AUTOSAR XML (schema 4-2-1)
standard types defined: boolean, float32, sint16, sint8, uint16, uint8, boolean_CompuMethod, boolean_DataConstr, float32_DataConstr, sint16_DataConstr, sint8_DataConstr, uint16_DataConstr, uint8_DataConstr
package /ComponentTypes
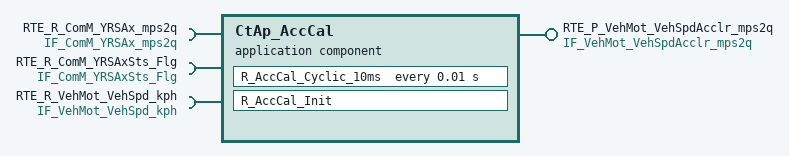
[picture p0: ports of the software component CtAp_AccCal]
  application sw component type CtAp_AccCal
    provide port RTE_P_VehMot_VehSpdAcclr_mps2q: nonqueued-sender-com-spec{data-element=tec_VehMot_VehSpdAcclr_mps2q, init-value=0}, provided-interface=IF_VehMot_VehSpdAcclr_mps2q
    require port RTE_R_ComM_YRSAx_mps2q: nonqueued-receiver-com-spec{data-element=tec_ComM_YRSAx_mps2q, filter=data-filter-type=ALWAYS, init-value=0}, required-interface=IF_ComM_YRSAx_mps2q
    require port RTE_R_ComM_YRSAxSts_Flg: nonqueued-receiver-com-spec{data-element=tec_ComM_YRSAxSts_Flg, filter=data-filter-type=ALWAYS, init-value=0}, required-interface=IF_ComM_YRSAxSts_Flg
    require port RTE_R_VehMot_VehSpd_kph: nonqueued-receiver-com-spec{data-element=tec_VehMot_VehSpd_kph, filter=data-filter-type=ALWAYS, init-value=0}, required-interface=IF_VehMot_VehSpd_kph
    behavior CtAp_AccCal_InternalBehavior
      timing event TMT_R_AccCal_Cyclic_10ms: start-on-event=R_AccCal_Cyclic_10ms, period=0.01
      init event CtAp_AccCal_InitEvent: start-on-event=R_AccCal_Init
      runnable R_AccCal_Cyclic_10ms
        data-receive-point-by-arguments:
          access REC_RTE_R_ComM_YRSAx_mps2q_tec_ComM_YRSAx_mps2q: accessed-variable=RTE_R_ComM_YRSAx_mps2q.tec_ComM_YRSAx_mps2q
          access REC_RTE_R_ComM_YRSAxSts_Flg_tec_ComM_YRSAxSts_Flg: accessed-variable=RTE_R_ComM_YRSAxSts_Flg.tec_ComM_YRSAxSts_Flg
          access REC_RTE_R_VehMot_VehSpd_kph_tec_VehMot_VehSpd_kph: accessed-variable=RTE_R_VehMot_VehSpd_kph.tec_VehMot_VehSpd_kph
        data-send-points:
          access SEND_RTE_P_VehMot_VehSpdAcclr_mps2q_tec_VehMot_VehSpdAcclr_mps2q: accessed-variable=RTE_P_VehMot_VehSpdAcclr_mps2q.tec_VehMot_VehSpdAcclr_mps2q
      runnable R_AccCal_Init
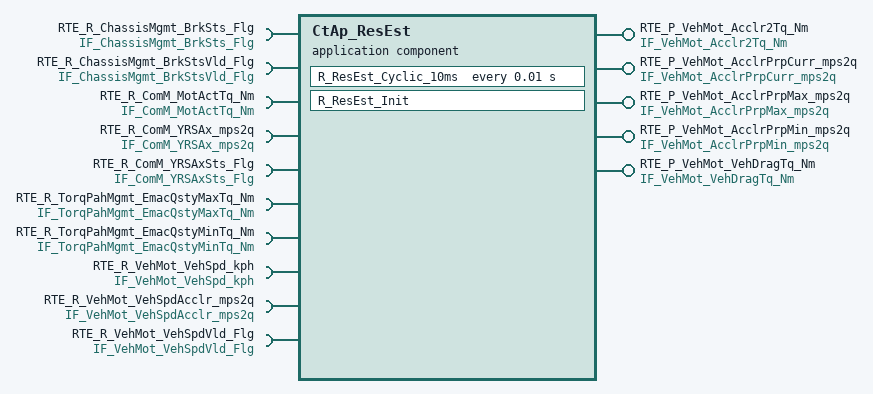
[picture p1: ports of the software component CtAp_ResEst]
  application sw component type CtAp_ResEst
    5 x provide port:
      RTE_P_VehMot_Acclr2Tq_Nm: nonqueued-sender-com-spec{data-element=tec_VehMot_Acclr2Tq_Nm, init-value=0}, provided-interface=IF_VehMot_Acclr2Tq_Nm
      RTE_P_VehMot_AcclrPrpCurr_mps2q: nonqueued-sender-com-spec{data-element=tec_VehMot_AcclrPrpCurr_mps2q, init-value=0}, provided-interface=IF_VehMot_AcclrPrpCurr_mps2q
      RTE_P_VehMot_AcclrPrpMax_mps2q: nonqueued-sender-com-spec{data-element=tec_VehMot_AcclrPrpMax_mps2q, init-value=0}, provided-interface=IF_VehMot_AcclrPrpMax_mps2q
      RTE_P_VehMot_AcclrPrpMin_mps2q: nonqueued-sender-com-spec{data-element=tec_VehMot_AcclrPrpMin_mps2q, init-value=0}, provided-interface=IF_VehMot_AcclrPrpMin_mps2q
      RTE_P_VehMot_VehDragTq_Nm: nonqueued-sender-com-spec{data-element=tec_VehMot_VehDragTq_Nm, init-value=0}, provided-interface=IF_VehMot_VehDragTq_Nm
    10 x require port:
      RTE_R_ChassisMgmt_BrkSts_Flg: nonqueued-receiver-com-spec{data-element=tec_ChassisMgmt_BrkSts_Flg, filter=data-filter-type=ALWAYS, init-value=0}, required-interface=IF_ChassisMgmt_BrkSts_Flg
      RTE_R_ChassisMgmt_BrkStsVld_Flg: nonqueued-receiver-com-spec{data-element=tec_ChassisMgmt_BrkStsVld_Flg, filter=data-filter-type=ALWAYS, init-value=0}, required-interface=IF_ChassisMgmt_BrkStsVld_Flg
      RTE_R_ComM_MotActTq_Nm: nonqueued-receiver-com-spec{data-element=tec_ComM_MotActTq_Nm, filter=data-filter-type=ALWAYS, init-value=0}, required-interface=IF_ComM_MotActTq_Nm
      RTE_R_ComM_YRSAx_mps2q: nonqueued-receiver-com-spec{data-element=tec_ComM_YRSAx_mps2q, filter=data-filter-type=ALWAYS, init-value=0}, required-interface=IF_ComM_YRSAx_mps2q
      RTE_R_ComM_YRSAxSts_Flg: nonqueued-receiver-com-spec{data-element=tec_ComM_YRSAxSts_Flg, filter=data-filter-type=ALWAYS, init-value=0}, required-interface=IF_ComM_YRSAxSts_Flg
      RTE_R_TorqPahMgmt_EmacQstyMaxTq_Nm: nonqueued-receiver-com-spec{data-element=tec_TorqPahMgmt_EmacQstyMaxTq_Nm, filter=data-filter-type=ALWAYS, init-value=0}, required-interface=IF_TorqPahMgmt_EmacQstyMaxTq_Nm
      RTE_R_TorqPahMgmt_EmacQstyMinTq_Nm: nonqueued-receiver-com-spec{data-element=tec_TorqPahMgmt_EmacQstyMinTq_Nm, filter=data-filter-type=ALWAYS, init-value=0}, required-interface=IF_TorqPahMgmt_EmacQstyMinTq_Nm
      RTE_R_VehMot_VehSpd_kph: nonqueued-receiver-com-spec{data-element=tec_VehMot_VehSpd_kph, filter=data-filter-type=ALWAYS, init-value=0}, required-interface=IF_VehMot_VehSpd_kph
      RTE_R_VehMot_VehSpdAcclr_mps2q: nonqueued-receiver-com-spec{data-element=tec_VehMot_VehSpdAcclr_mps2q, filter=data-filter-type=ALWAYS, init-value=0}, required-interface=IF_VehMot_VehSpdAcclr_mps2q
      RTE_R_VehMot_VehSpdVld_Flg: nonqueued-receiver-com-spec{data-element=tec_VehMot_VehSpdVld_Flg, filter=data-filter-type=ALWAYS, init-value=0}, required-interface=IF_VehMot_VehSpdVld_Flg
    behavior CtAp_ResEst_InternalBehavior
      timing event TMT_R_ResEst_Cyclic_10ms: start-on-event=R_ResEst_Cyclic_10ms, period=0.01
      init event CtAp_ResEst_InitEvent: start-on-event=R_ResEst_Init
      runnable R_ResEst_Cyclic_10ms
        data-receive-point-by-arguments:
          10 x access:
            REC_RTE_R_ChassisMgmt_BrkSts_Flg_tec_ChassisMgmt_BrkSts_Flg: accessed-variable=RTE_R_ChassisMgmt_BrkSts_Flg.tec_ChassisMgmt_BrkSts_Flg
            REC_RTE_R_ChassisMgmt_BrkStsVld_Flg_tec_ChassisMgmt_BrkStsVld_Flg: accessed-variable=RTE_R_ChassisMgmt_BrkStsVld_Flg.tec_ChassisMgmt_BrkStsVld_Flg
            REC_RTE_R_ComM_MotActTq_Nm_tec_ComM_MotActTq_Nm: accessed-variable=RTE_R_ComM_MotActTq_Nm.tec_ComM_MotActTq_Nm
            REC_RTE_R_ComM_YRSAx_mps2q_tec_ComM_YRSAx_mps2q: accessed-variable=RTE_R_ComM_YRSAx_mps2q.tec_ComM_YRSAx_mps2q
            REC_RTE_R_ComM_YRSAxSts_Flg_tec_ComM_YRSAxSts_Flg: accessed-variable=RTE_R_ComM_YRSAxSts_Flg.tec_ComM_YRSAxSts_Flg
            REC_RTE_R_TorqPahMgmt_EmacQstyMaxTq_Nm_tec_TorqPahMgmt_EmacQstyMaxTq_Nm: accessed-variable=RTE_R_TorqPahMgmt_EmacQstyMaxTq_Nm.tec_TorqPahMgmt_EmacQstyMaxTq_Nm
            REC_RTE_R_TorqPahMgmt_EmacQstyMinTq_Nm_tec_TorqPahMgmt_EmacQstyMinTq_Nm: accessed-variable=RTE_R_TorqPahMgmt_EmacQstyMinTq_Nm.tec_TorqPahMgmt_EmacQstyMinTq_Nm
            REC_RTE_R_VehMot_VehSpd_kph_tec_VehMot_VehSpd_kph: accessed-variable=RTE_R_VehMot_VehSpd_kph.tec_VehMot_VehSpd_kph
            REC_RTE_R_VehMot_VehSpdAcclr_mps2q_tec_VehMot_VehSpdAcclr_mps2q: accessed-variable=RTE_R_VehMot_VehSpdAcclr_mps2q.tec_VehMot_VehSpdAcclr_mps2q
            REC_RTE_R_VehMot_VehSpdVld_Flg_tec_VehMot_VehSpdVld_Flg: accessed-variable=RTE_R_VehMot_VehSpdVld_Flg.tec_VehMot_VehSpdVld_Flg
        data-send-points:
          5 x access:
            SEND_RTE_P_VehMot_Acclr2Tq_Nm_tec_VehMot_Acclr2Tq_Nm: accessed-variable=RTE_P_VehMot_Acclr2Tq_Nm.tec_VehMot_Acclr2Tq_Nm
            SEND_RTE_P_VehMot_AcclrPrpCurr_mps2q_tec_VehMot_AcclrPrpCurr_mps2q: accessed-variable=RTE_P_VehMot_AcclrPrpCurr_mps2q.tec_VehMot_AcclrPrpCurr_mps2q
            SEND_RTE_P_VehMot_AcclrPrpMax_mps2q_tec_VehMot_AcclrPrpMax_mps2q: accessed-variable=RTE_P_VehMot_AcclrPrpMax_mps2q.tec_VehMot_AcclrPrpMax_mps2q
            SEND_RTE_P_VehMot_AcclrPrpMin_mps2q_tec_VehMot_AcclrPrpMin_mps2q: accessed-variable=RTE_P_VehMot_AcclrPrpMin_mps2q.tec_VehMot_AcclrPrpMin_mps2q
            SEND_RTE_P_VehMot_VehDragTq_Nm_tec_VehMot_VehDragTq_Nm: accessed-variable=RTE_P_VehMot_VehDragTq_Nm.tec_VehMot_VehDragTq_Nm
      runnable R_ResEst_Init
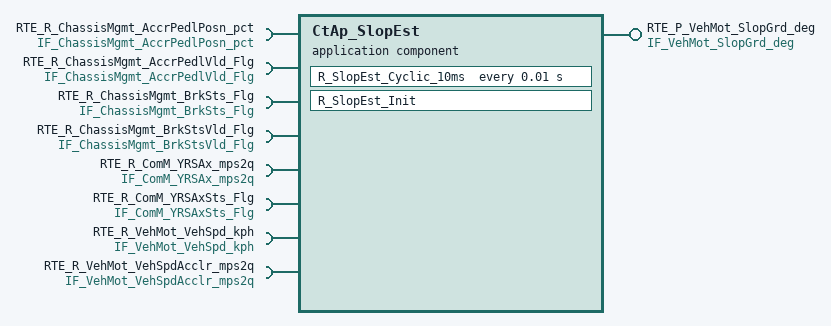
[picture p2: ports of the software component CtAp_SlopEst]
  application sw component type CtAp_SlopEst
    provide port RTE_P_VehMot_SlopGrd_deg: nonqueued-sender-com-spec{data-element=tec_VehMot_SlopGrd_deg, init-value=0}, provided-interface=IF_VehMot_SlopGrd_deg
    8 x require port:
      RTE_R_ChassisMgmt_AccrPedlPosn_pct: nonqueued-receiver-com-spec{data-element=tec_ChassisMgmt_AccrPedlPosn_pct, filter=data-filter-type=ALWAYS, init-value=0}, required-interface=IF_ChassisMgmt_AccrPedlPosn_pct
      RTE_R_ChassisMgmt_AccrPedlVld_Flg: nonqueued-receiver-com-spec{data-element=tec_ChassisMgmt_AccrPedlVld_Flg, filter=data-filter-type=ALWAYS, init-value=0}, required-interface=IF_ChassisMgmt_AccrPedlVld_Flg
      RTE_R_ChassisMgmt_BrkSts_Flg: nonqueued-receiver-com-spec{data-element=tec_ChassisMgmt_BrkSts_Flg, filter=data-filter-type=ALWAYS, init-value=0}, required-interface=IF_ChassisMgmt_BrkSts_Flg
      RTE_R_ChassisMgmt_BrkStsVld_Flg: nonqueued-receiver-com-spec{data-element=tec_ChassisMgmt_BrkStsVld_Flg, filter=data-filter-type=ALWAYS, init-value=0}, required-interface=IF_ChassisMgmt_BrkStsVld_Flg
      RTE_R_ComM_YRSAx_mps2q: nonqueued-receiver-com-spec{data-element=tec_ComM_YRSAx_mps2q, filter=data-filter-type=ALWAYS, init-value=0}, required-interface=IF_ComM_YRSAx_mps2q
      RTE_R_ComM_YRSAxSts_Flg: nonqueued-receiver-com-spec{data-element=tec_ComM_YRSAxSts_Flg, filter=data-filter-type=ALWAYS, init-value=0}, required-interface=IF_ComM_YRSAxSts_Flg
      RTE_R_VehMot_VehSpd_kph: nonqueued-receiver-com-spec{data-element=tec_VehMot_VehSpd_kph, filter=data-filter-type=ALWAYS, init-value=0}, required-interface=IF_VehMot_VehSpd_kph
      RTE_R_VehMot_VehSpdAcclr_mps2q: nonqueued-receiver-com-spec{data-element=tec_VehMot_VehSpdAcclr_mps2q, filter=data-filter-type=ALWAYS, init-value=0}, required-interface=IF_VehMot_VehSpdAcclr_mps2q
    behavior CtAp_SlopEst_InternalBehavior
      timing event TMT_R_SlopEst_Cyclic_10ms: start-on-event=R_SlopEst_Cyclic_10ms, period=0.01
      init event CtAp_SlopEst_InitEvent: start-on-event=R_SlopEst_Init
      runnable R_SlopEst_Cyclic_10ms
        data-receive-point-by-arguments:
          8 x access:
            REC_RTE_R_ChassisMgmt_AccrPedlPosn_pct_tec_ChassisMgmt_AccrPedlPosn_pct: accessed-variable=RTE_R_ChassisMgmt_AccrPedlPosn_pct.tec_ChassisMgmt_AccrPedlPosn_pct
            REC_RTE_R_ChassisMgmt_AccrPedlVld_Flg_tec_ChassisMgmt_AccrPedlVld_Flg: accessed-variable=RTE_R_ChassisMgmt_AccrPedlVld_Flg.tec_ChassisMgmt_AccrPedlVld_Flg
            REC_RTE_R_ChassisMgmt_BrkSts_Flg_tec_ChassisMgmt_BrkSts_Flg: accessed-variable=RTE_R_ChassisMgmt_BrkSts_Flg.tec_ChassisMgmt_BrkSts_Flg
            REC_RTE_R_ChassisMgmt_BrkStsVld_Flg_tec_ChassisMgmt_BrkStsVld_Flg: accessed-variable=RTE_R_ChassisMgmt_BrkStsVld_Flg.tec_ChassisMgmt_BrkStsVld_Flg
            REC_RTE_R_ComM_YRSAx_mps2q_tec_ComM_YRSAx_mps2q: accessed-variable=RTE_R_ComM_YRSAx_mps2q.tec_ComM_YRSAx_mps2q
            REC_RTE_R_ComM_YRSAxSts_Flg_tec_ComM_YRSAxSts_Flg: accessed-variable=RTE_R_ComM_YRSAxSts_Flg.tec_ComM_YRSAxSts_Flg
            REC_RTE_R_VehMot_VehSpd_kph_tec_VehMot_VehSpd_kph: accessed-variable=RTE_R_VehMot_VehSpd_kph.tec_VehMot_VehSpd_kph
            REC_RTE_R_VehMot_VehSpdAcclr_mps2q_tec_VehMot_VehSpdAcclr_mps2q: accessed-variable=RTE_R_VehMot_VehSpdAcclr_mps2q.tec_VehMot_VehSpdAcclr_mps2q
        data-send-points:
          access SEND_RTE_P_VehMot_SlopGrd_deg_tec_VehMot_SlopGrd_deg: accessed-variable=RTE_P_VehMot_SlopGrd_deg.tec_VehMot_SlopGrd_deg
      runnable R_SlopEst_Init
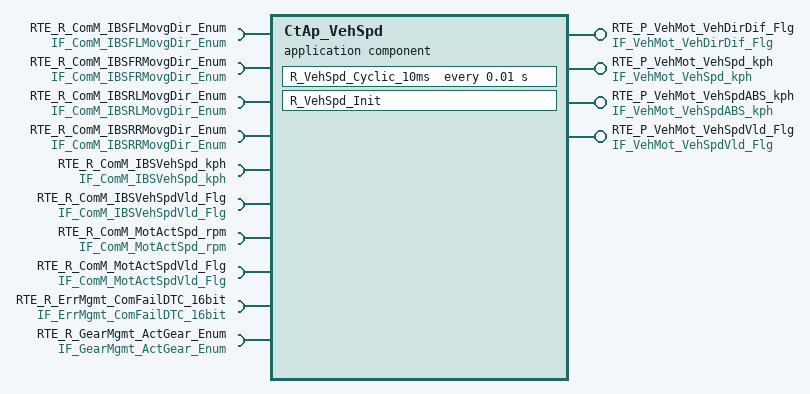
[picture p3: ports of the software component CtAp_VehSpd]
  application sw component type CtAp_VehSpd
    4 x provide port:
      RTE_P_VehMot_VehDirDif_Flg: nonqueued-sender-com-spec{data-element=tec_VehMot_VehDirDif_Flg, init-value=0}, provided-interface=IF_VehMot_VehDirDif_Flg
      RTE_P_VehMot_VehSpd_kph: nonqueued-sender-com-spec{data-element=tec_VehMot_VehSpd_kph, init-value=0}, provided-interface=IF_VehMot_VehSpd_kph
      RTE_P_VehMot_VehSpdABS_kph: nonqueued-sender-com-spec{data-element=tec_VehMot_VehSpdABS_kph, init-value=0}, provided-interface=IF_VehMot_VehSpdABS_kph
      RTE_P_VehMot_VehSpdVld_Flg: nonqueued-sender-com-spec{data-element=tec_VehMot_VehSpdVld_Flg, init-value=0}, provided-interface=IF_VehMot_VehSpdVld_Flg
    10 x require port:
      RTE_R_ComM_IBSFLMovgDir_Enum: nonqueued-receiver-com-spec{data-element=tec_ComM_IBSFLMovgDir_Enum, filter=data-filter-type=ALWAYS, init-value=0}, required-interface=IF_ComM_IBSFLMovgDir_Enum
      RTE_R_ComM_IBSFRMovgDir_Enum: nonqueued-receiver-com-spec{data-element=tec_ComM_IBSFRMovgDir_Enum, filter=data-filter-type=ALWAYS, init-value=0}, required-interface=IF_ComM_IBSFRMovgDir_Enum
      RTE_R_ComM_IBSRLMovgDir_Enum: nonqueued-receiver-com-spec{data-element=tec_ComM_IBSRLMovgDir_Enum, filter=data-filter-type=ALWAYS, init-value=0}, required-interface=IF_ComM_IBSRLMovgDir_Enum
      RTE_R_ComM_IBSRRMovgDir_Enum: nonqueued-receiver-com-spec{data-element=tec_ComM_IBSRRMovgDir_Enum, filter=data-filter-type=ALWAYS, init-value=0}, required-interface=IF_ComM_IBSRRMovgDir_Enum
      RTE_R_ComM_IBSVehSpd_kph: nonqueued-receiver-com-spec{data-element=tec_ComM_IBSVehSpd_kph, filter=data-filter-type=ALWAYS, init-value=0}, required-interface=IF_ComM_IBSVehSpd_kph
      RTE_R_ComM_IBSVehSpdVld_Flg: nonqueued-receiver-com-spec{data-element=tec_ComM_IBSVehSpdVld_Flg, filter=data-filter-type=ALWAYS, init-value=0}, required-interface=IF_ComM_IBSVehSpdVld_Flg
      RTE_R_ComM_MotActSpd_rpm: nonqueued-receiver-com-spec{data-element=tec_ComM_MotActSpd_rpm, filter=data-filter-type=ALWAYS, init-value=0}, required-interface=IF_ComM_MotActSpd_rpm
      RTE_R_ComM_MotActSpdVld_Flg: nonqueued-receiver-com-spec{data-element=tec_ComM_MotActSpdVld_Flg, filter=data-filter-type=ALWAYS, init-value=0}, required-interface=IF_ComM_MotActSpdVld_Flg
      RTE_R_ErrMgmt_ComFailDTC_16bit: nonqueued-receiver-com-spec{data-element=tec_ErrMgmt_ComFailDTC_16bit, filter=data-filter-type=ALWAYS, init-value=0}, required-interface=IF_ErrMgmt_ComFailDTC_16bit
      RTE_R_GearMgmt_ActGear_Enum: nonqueued-receiver-com-spec{data-element=tec_GearMgmt_ActGear_Enum, filter=data-filter-type=ALWAYS, init-value=0}, required-interface=IF_GearMgmt_ActGear_Enum
    behavior CtAp_VehSpd_InternalBehavior
      timing event TMT_R_VehSpd_Cyclic_10ms: start-on-event=R_VehSpd_Cyclic_10ms, period=0.01
      init event CtAp_VehSpd_InitEvent: start-on-event=R_VehSpd_Init
      runnable R_VehSpd_Cyclic_10ms
        data-receive-point-by-arguments:
          10 x access:
            REC_RTE_R_ComM_IBSFLMovgDir_Enum_tec_ComM_IBSFLMovgDir_Enum: accessed-variable=RTE_R_ComM_IBSFLMovgDir_Enum.tec_ComM_IBSFLMovgDir_Enum
            REC_RTE_R_ComM_IBSFRMovgDir_Enum_tec_ComM_IBSFRMovgDir_Enum: accessed-variable=RTE_R_ComM_IBSFRMovgDir_Enum.tec_ComM_IBSFRMovgDir_Enum
            REC_RTE_R_ComM_IBSRLMovgDir_Enum_tec_ComM_IBSRLMovgDir_Enum: accessed-variable=RTE_R_ComM_IBSRLMovgDir_Enum.tec_ComM_IBSRLMovgDir_Enum
            REC_RTE_R_ComM_IBSRRMovgDir_Enum_tec_ComM_IBSRRMovgDir_Enum: accessed-variable=RTE_R_ComM_IBSRRMovgDir_Enum.tec_ComM_IBSRRMovgDir_Enum
            REC_RTE_R_ComM_IBSVehSpd_kph_tec_ComM_IBSVehSpd_kph: accessed-variable=RTE_R_ComM_IBSVehSpd_kph.tec_ComM_IBSVehSpd_kph
            REC_RTE_R_ComM_IBSVehSpdVld_Flg_tec_ComM_IBSVehSpdVld_Flg: accessed-variable=RTE_R_ComM_IBSVehSpdVld_Flg.tec_ComM_IBSVehSpdVld_Flg
            REC_RTE_R_ComM_MotActSpd_rpm_tec_ComM_MotActSpd_rpm: accessed-variable=RTE_R_ComM_MotActSpd_rpm.tec_ComM_MotActSpd_rpm
            REC_RTE_R_ComM_MotActSpdVld_Flg_tec_ComM_MotActSpdVld_Flg: accessed-variable=RTE_R_ComM_MotActSpdVld_Flg.tec_ComM_MotActSpdVld_Flg
            REC_RTE_R_ErrMgmt_ComFailDTC_16bit_tec_ErrMgmt_ComFailDTC_16bit: accessed-variable=RTE_R_ErrMgmt_ComFailDTC_16bit.tec_ErrMgmt_ComFailDTC_16bit
            REC_RTE_R_GearMgmt_ActGear_Enum_tec_GearMgmt_ActGear_Enum: accessed-variable=RTE_R_GearMgmt_ActGear_Enum.tec_GearMgmt_ActGear_Enum
        data-send-points:
          4 x access:
            SEND_RTE_P_VehMot_VehDirDif_Flg_tec_VehMot_VehDirDif_Flg: accessed-variable=RTE_P_VehMot_VehDirDif_Flg.tec_VehMot_VehDirDif_Flg
            SEND_RTE_P_VehMot_VehSpd_kph_tec_VehMot_VehSpd_kph: accessed-variable=RTE_P_VehMot_VehSpd_kph.tec_VehMot_VehSpd_kph
            SEND_RTE_P_VehMot_VehSpdABS_kph_tec_VehMot_VehSpdABS_kph: accessed-variable=RTE_P_VehMot_VehSpdABS_kph.tec_VehMot_VehSpdABS_kph
            SEND_RTE_P_VehMot_VehSpdVld_Flg_tec_VehMot_VehSpdVld_Flg: accessed-variable=RTE_P_VehMot_VehSpdVld_Flg.tec_VehMot_VehSpdVld_Flg
      runnable R_VehSpd_Init
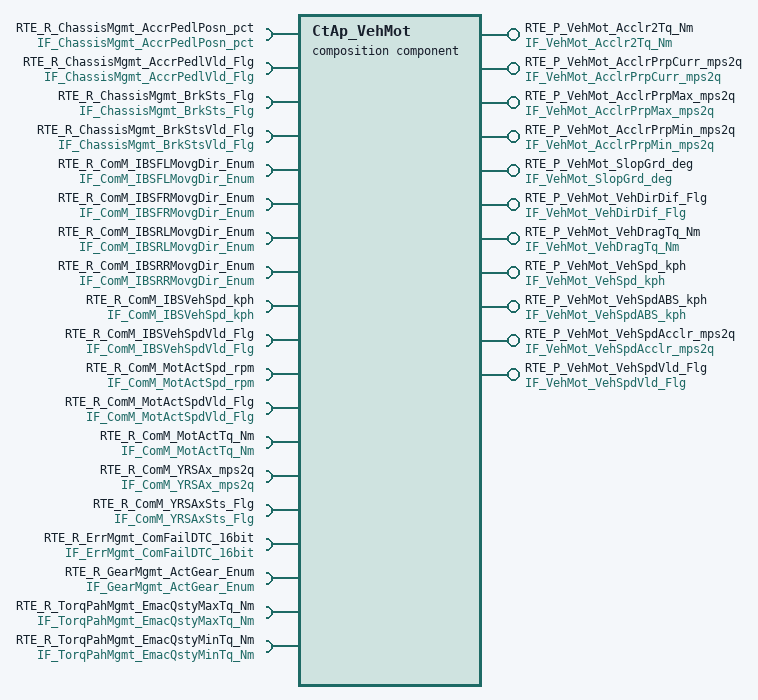
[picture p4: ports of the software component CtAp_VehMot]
  composition sw component type CtAp_VehMot
    11 x provide port:
      RTE_P_VehMot_Acclr2Tq_Nm: nonqueued-sender-com-spec{data-element=tec_VehMot_Acclr2Tq_Nm, init-value=0}, provided-interface=IF_VehMot_Acclr2Tq_Nm
      RTE_P_VehMot_AcclrPrpCurr_mps2q: nonqueued-sender-com-spec{data-element=tec_VehMot_AcclrPrpCurr_mps2q, init-value=0}, provided-interface=IF_VehMot_AcclrPrpCurr_mps2q
      RTE_P_VehMot_AcclrPrpMax_mps2q: nonqueued-sender-com-spec{data-element=tec_VehMot_AcclrPrpMax_mps2q, init-value=0}, provided-interface=IF_VehMot_AcclrPrpMax_mps2q
      RTE_P_VehMot_AcclrPrpMin_mps2q: nonqueued-sender-com-spec{data-element=tec_VehMot_AcclrPrpMin_mps2q, init-value=0}, provided-interface=IF_VehMot_AcclrPrpMin_mps2q
      RTE_P_VehMot_SlopGrd_deg: nonqueued-sender-com-spec{data-element=tec_VehMot_SlopGrd_deg, init-value=0}, provided-interface=IF_VehMot_SlopGrd_deg
      RTE_P_VehMot_VehDirDif_Flg: nonqueued-sender-com-spec{data-element=tec_VehMot_VehDirDif_Flg, init-value=0}, provided-interface=IF_VehMot_VehDirDif_Flg
      RTE_P_VehMot_VehDragTq_Nm: nonqueued-sender-com-spec{data-element=tec_VehMot_VehDragTq_Nm, init-value=0}, provided-interface=IF_VehMot_VehDragTq_Nm
      RTE_P_VehMot_VehSpd_kph: nonqueued-sender-com-spec{data-element=tec_VehMot_VehSpd_kph, init-value=0}, provided-interface=IF_VehMot_VehSpd_kph
      RTE_P_VehMot_VehSpdABS_kph: nonqueued-sender-com-spec{data-element=tec_VehMot_VehSpdABS_kph, init-value=0}, provided-interface=IF_VehMot_VehSpdABS_kph
      RTE_P_VehMot_VehSpdAcclr_mps2q: nonqueued-sender-com-spec{data-element=tec_VehMot_VehSpdAcclr_mps2q, init-value=0}, provided-interface=IF_VehMot_VehSpdAcclr_mps2q
      RTE_P_VehMot_VehSpdVld_Flg: nonqueued-sender-com-spec{data-element=tec_VehMot_VehSpdVld_Flg, init-value=0}, provided-interface=IF_VehMot_VehSpdVld_Flg
    19 x require port:
      RTE_R_ChassisMgmt_AccrPedlPosn_pct: nonqueued-receiver-com-spec{data-element=tec_ChassisMgmt_AccrPedlPosn_pct, filter=data-filter-type=ALWAYS, init-value=0}, required-interface=IF_ChassisMgmt_AccrPedlPosn_pct
      RTE_R_ChassisMgmt_AccrPedlVld_Flg: nonqueued-receiver-com-spec{data-element=tec_ChassisMgmt_AccrPedlVld_Flg, filter=data-filter-type=ALWAYS, init-value=0}, required-interface=IF_ChassisMgmt_AccrPedlVld_Flg
      RTE_R_ChassisMgmt_BrkSts_Flg: nonqueued-receiver-com-spec{data-element=tec_ChassisMgmt_BrkSts_Flg, filter=data-filter-type=ALWAYS, init-value=0}, required-interface=IF_ChassisMgmt_BrkSts_Flg
      RTE_R_ChassisMgmt_BrkStsVld_Flg: nonqueued-receiver-com-spec{data-element=tec_ChassisMgmt_BrkStsVld_Flg, filter=data-filter-type=ALWAYS, init-value=0}, required-interface=IF_ChassisMgmt_BrkStsVld_Flg
      RTE_R_ComM_IBSFLMovgDir_Enum: nonqueued-receiver-com-spec{data-element=tec_ComM_IBSFLMovgDir_Enum, filter=data-filter-type=ALWAYS, init-value=0}, required-interface=IF_ComM_IBSFLMovgDir_Enum
      RTE_R_ComM_IBSFRMovgDir_Enum: nonqueued-receiver-com-spec{data-element=tec_ComM_IBSFRMovgDir_Enum, filter=data-filter-type=ALWAYS, init-value=0}, required-interface=IF_ComM_IBSFRMovgDir_Enum
      RTE_R_ComM_IBSRLMovgDir_Enum: nonqueued-receiver-com-spec{data-element=tec_ComM_IBSRLMovgDir_Enum, filter=data-filter-type=ALWAYS, init-value=0}, required-interface=IF_ComM_IBSRLMovgDir_Enum
      RTE_R_ComM_IBSRRMovgDir_Enum: nonqueued-receiver-com-spec{data-element=tec_ComM_IBSRRMovgDir_Enum, filter=data-filter-type=ALWAYS, init-value=0}, required-interface=IF_ComM_IBSRRMovgDir_Enum
      RTE_R_ComM_IBSVehSpd_kph: nonqueued-receiver-com-spec{data-element=tec_ComM_IBSVehSpd_kph, filter=data-filter-type=ALWAYS, init-value=0}, required-interface=IF_ComM_IBSVehSpd_kph
      RTE_R_ComM_IBSVehSpdVld_Flg: nonqueued-receiver-com-spec{data-element=tec_ComM_IBSVehSpdVld_Flg, filter=data-filter-type=ALWAYS, init-value=0}, required-interface=IF_ComM_IBSVehSpdVld_Flg
      RTE_R_ComM_MotActSpd_rpm: nonqueued-receiver-com-spec{data-element=tec_ComM_MotActSpd_rpm, filter=data-filter-type=ALWAYS, init-value=0}, required-interface=IF_ComM_MotActSpd_rpm
      RTE_R_ComM_MotActSpdVld_Flg: nonqueued-receiver-com-spec{data-element=tec_ComM_MotActSpdVld_Flg, filter=data-filter-type=ALWAYS, init-value=0}, required-interface=IF_ComM_MotActSpdVld_Flg
      RTE_R_ComM_MotActTq_Nm: nonqueued-receiver-com-spec{data-element=tec_ComM_MotActTq_Nm, filter=data-filter-type=ALWAYS, init-value=0}, required-interface=IF_ComM_MotActTq_Nm
      RTE_R_ComM_YRSAx_mps2q: nonqueued-receiver-com-spec{data-element=tec_ComM_YRSAx_mps2q, filter=data-filter-type=ALWAYS, init-value=0}, required-interface=IF_ComM_YRSAx_mps2q
      RTE_R_ComM_YRSAxSts_Flg: nonqueued-receiver-com-spec{data-element=tec_ComM_YRSAxSts_Flg, filter=data-filter-type=ALWAYS, init-value=0}, required-interface=IF_ComM_YRSAxSts_Flg
      RTE_R_ErrMgmt_ComFailDTC_16bit: nonqueued-receiver-com-spec{data-element=tec_ErrMgmt_ComFailDTC_16bit, filter=data-filter-type=ALWAYS, init-value=0}, required-interface=IF_ErrMgmt_ComFailDTC_16bit
      RTE_R_GearMgmt_ActGear_Enum: nonqueued-receiver-com-spec{data-element=tec_GearMgmt_ActGear_Enum, filter=data-filter-type=ALWAYS, init-value=0}, required-interface=IF_GearMgmt_ActGear_Enum
      RTE_R_TorqPahMgmt_EmacQstyMaxTq_Nm: nonqueued-receiver-com-spec{data-element=tec_TorqPahMgmt_EmacQstyMaxTq_Nm, filter=data-filter-type=ALWAYS, init-value=0}, required-interface=IF_TorqPahMgmt_EmacQstyMaxTq_Nm
      RTE_R_TorqPahMgmt_EmacQstyMinTq_Nm: nonqueued-receiver-com-spec{data-element=tec_TorqPahMgmt_EmacQstyMinTq_Nm, filter=data-filter-type=ALWAYS, init-value=0}, required-interface=IF_TorqPahMgmt_EmacQstyMinTq_Nm
    4 x component:
      CtAp_AccCal: type=CtAp_AccCal
      CtAp_ResEst: type=CtAp_ResEst
      CtAp_SlopEst: type=CtAp_SlopEst
      CtAp_VehSpd: type=CtAp_VehSpd
    connect CtAp_AccCal.RTE_P_VehMot_VehSpdAcclr_mps2q -> CtAp_ResEst.RTE_R_VehMot_VehSpdAcclr_mps2q
    connect CtAp_AccCal.RTE_P_VehMot_VehSpdAcclr_mps2q -> CtAp_SlopEst.RTE_R_VehMot_VehSpdAcclr_mps2q
    connect CtAp_VehSpd.RTE_P_VehMot_VehSpd_kph -> CtAp_AccCal.RTE_R_VehMot_VehSpd_kph
    connect CtAp_VehSpd.RTE_P_VehMot_VehSpd_kph -> CtAp_ResEst.RTE_R_VehMot_VehSpd_kph
    connect CtAp_VehSpd.RTE_P_VehMot_VehSpdVld_Flg -> CtAp_ResEst.RTE_R_VehMot_VehSpdVld_Flg
    connect CtAp_VehSpd.RTE_P_VehMot_VehSpd_kph -> CtAp_SlopEst.RTE_R_VehMot_VehSpd_kph
    delegate CtAp_ResEst.RTE_P_VehMot_Acclr2Tq_Nm <-> outer port CtAp_VehMot/RTE_P_VehMot_Acclr2Tq_Nm
    delegate CtAp_ResEst.RTE_P_VehMot_AcclrPrpCurr_mps2q <-> outer port CtAp_VehMot/RTE_P_VehMot_AcclrPrpCurr_mps2q
    delegate CtAp_ResEst.RTE_P_VehMot_AcclrPrpMax_mps2q <-> outer port CtAp_VehMot/RTE_P_VehMot_AcclrPrpMax_mps2q
    delegate CtAp_ResEst.RTE_P_VehMot_AcclrPrpMin_mps2q <-> outer port CtAp_VehMot/RTE_P_VehMot_AcclrPrpMin_mps2q
    delegate CtAp_SlopEst.RTE_P_VehMot_SlopGrd_deg <-> outer port CtAp_VehMot/RTE_P_VehMot_SlopGrd_deg
    delegate CtAp_VehSpd.RTE_P_VehMot_VehDirDif_Flg <-> outer port CtAp_VehMot/RTE_P_VehMot_VehDirDif_Flg
    delegate CtAp_ResEst.RTE_P_VehMot_VehDragTq_Nm <-> outer port CtAp_VehMot/RTE_P_VehMot_VehDragTq_Nm
    delegate CtAp_VehSpd.RTE_P_VehMot_VehSpd_kph <-> outer port CtAp_VehMot/RTE_P_VehMot_VehSpd_kph
    delegate CtAp_VehSpd.RTE_P_VehMot_VehSpdABS_kph <-> outer port CtAp_VehMot/RTE_P_VehMot_VehSpdABS_kph
    delegate CtAp_AccCal.RTE_P_VehMot_VehSpdAcclr_mps2q <-> outer port CtAp_VehMot/RTE_P_VehMot_VehSpdAcclr_mps2q
    delegate CtAp_VehSpd.RTE_P_VehMot_VehSpdVld_Flg <-> outer port CtAp_VehMot/RTE_P_VehMot_VehSpdVld_Flg
    delegate CtAp_SlopEst.RTE_R_ChassisMgmt_AccrPedlPosn_pct <-> outer port CtAp_VehMot/RTE_R_ChassisMgmt_AccrPedlPosn_pct
    delegate CtAp_SlopEst.RTE_R_ChassisMgmt_AccrPedlVld_Flg <-> outer port CtAp_VehMot/RTE_R_ChassisMgmt_AccrPedlVld_Flg
    delegate CtAp_ResEst.RTE_R_ChassisMgmt_BrkSts_Flg <-> outer port CtAp_VehMot/RTE_R_ChassisMgmt_BrkSts_Flg
    delegate CtAp_SlopEst.RTE_R_ChassisMgmt_BrkSts_Flg <-> outer port CtAp_VehMot/RTE_R_ChassisMgmt_BrkSts_Flg
    delegate CtAp_ResEst.RTE_R_ChassisMgmt_BrkStsVld_Flg <-> outer port CtAp_VehMot/RTE_R_ChassisMgmt_BrkStsVld_Flg
    delegate CtAp_SlopEst.RTE_R_ChassisMgmt_BrkStsVld_Flg <-> outer port CtAp_VehMot/RTE_R_ChassisMgmt_BrkStsVld_Flg
    delegate CtAp_VehSpd.RTE_R_ComM_IBSFLMovgDir_Enum <-> outer port CtAp_VehMot/RTE_R_ComM_IBSFLMovgDir_Enum
    delegate CtAp_VehSpd.RTE_R_ComM_IBSFRMovgDir_Enum <-> outer port CtAp_VehMot/RTE_R_ComM_IBSFRMovgDir_Enum
    delegate CtAp_VehSpd.RTE_R_ComM_IBSRLMovgDir_Enum <-> outer port CtAp_VehMot/RTE_R_ComM_IBSRLMovgDir_Enum
    delegate CtAp_VehSpd.RTE_R_ComM_IBSRRMovgDir_Enum <-> outer port CtAp_VehMot/RTE_R_ComM_IBSRRMovgDir_Enum
    delegate CtAp_VehSpd.RTE_R_ComM_IBSVehSpd_kph <-> outer port CtAp_VehMot/RTE_R_ComM_IBSVehSpd_kph
    delegate CtAp_VehSpd.RTE_R_ComM_IBSVehSpdVld_Flg <-> outer port CtAp_VehMot/RTE_R_ComM_IBSVehSpdVld_Flg
    delegate CtAp_VehSpd.RTE_R_ComM_MotActSpd_rpm <-> outer port CtAp_VehMot/RTE_R_ComM_MotActSpd_rpm
    delegate CtAp_VehSpd.RTE_R_ComM_MotActSpdVld_Flg <-> outer port CtAp_VehMot/RTE_R_ComM_MotActSpdVld_Flg
    delegate CtAp_ResEst.RTE_R_ComM_MotActTq_Nm <-> outer port CtAp_VehMot/RTE_R_ComM_MotActTq_Nm
    delegate CtAp_AccCal.RTE_R_ComM_YRSAx_mps2q <-> outer port CtAp_VehMot/RTE_R_ComM_YRSAx_mps2q
    delegate CtAp_ResEst.RTE_R_ComM_YRSAx_mps2q <-> outer port CtAp_VehMot/RTE_R_ComM_YRSAx_mps2q
    delegate CtAp_SlopEst.RTE_R_ComM_YRSAx_mps2q <-> outer port CtAp_VehMot/RTE_R_ComM_YRSAx_mps2q
    delegate CtAp_AccCal.RTE_R_ComM_YRSAxSts_Flg <-> outer port CtAp_VehMot/RTE_R_ComM_YRSAxSts_Flg
    delegate CtAp_ResEst.RTE_R_ComM_YRSAxSts_Flg <-> outer port CtAp_VehMot/RTE_R_ComM_YRSAxSts_Flg
    delegate CtAp_SlopEst.RTE_R_ComM_YRSAxSts_Flg <-> outer port CtAp_VehMot/RTE_R_ComM_YRSAxSts_Flg
    delegate CtAp_VehSpd.RTE_R_ErrMgmt_ComFailDTC_16bit <-> outer port CtAp_VehMot/RTE_R_ErrMgmt_ComFailDTC_16bit
    delegate CtAp_VehSpd.RTE_R_GearMgmt_ActGear_Enum <-> outer port CtAp_VehMot/RTE_R_GearMgmt_ActGear_Enum
    delegate CtAp_ResEst.RTE_R_TorqPahMgmt_EmacQstyMaxTq_Nm <-> outer port CtAp_VehMot/RTE_R_TorqPahMgmt_EmacQstyMaxTq_Nm
    delegate CtAp_ResEst.RTE_R_TorqPahMgmt_EmacQstyMinTq_Nm <-> outer port CtAp_VehMot/RTE_R_TorqPahMgmt_EmacQstyMinTq_Nm
  4 x swc implementation:
    CtAp_AccCal_Implementation: behavior=CtAp_AccCal_InternalBehavior
      code-descriptors:
        code Default: artifact-descriptors=autosar-engineering-object={short-label=Default, category=SWOBJ}
    CtAp_ResEst_Implementation: behavior=CtAp_ResEst_InternalBehavior
      code-descriptors:
        code Default: artifact-descriptors=autosar-engineering-object={short-label=Default, category=SWOBJ}
    CtAp_SlopEst_Implementation: behavior=CtAp_SlopEst_InternalBehavior
      code-descriptors:
        code Default: artifact-descriptors=autosar-engineering-object={short-label=Default, category=SWOBJ}
    CtAp_VehSpd_Implementation: behavior=CtAp_VehSpd_InternalBehavior
      code-descriptors:
        code Default: artifact-descriptors=autosar-engineering-object={short-label=Default, category=SWOBJ}
package /PortInterfaces
  30 x sender receiver interface:
    IF_ChassisMgmt_AccrPedlPosn_pct: invalidation-policy{data-element=tec_ChassisMgmt_AccrPedlPosn_pct, handle-invalid=DONT-INVALIDATE}
      data tec_ChassisMgmt_AccrPedlPosn_pct: type=float32
    IF_ChassisMgmt_AccrPedlVld_Flg: invalidation-policy{data-element=tec_ChassisMgmt_AccrPedlVld_Flg, handle-invalid=DONT-INVALIDATE}
      data tec_ChassisMgmt_AccrPedlVld_Flg: type=boolean
    IF_ChassisMgmt_BrkSts_Flg: invalidation-policy{data-element=tec_ChassisMgmt_BrkSts_Flg, handle-invalid=DONT-INVALIDATE}
      data tec_ChassisMgmt_BrkSts_Flg: type=boolean
    IF_ChassisMgmt_BrkStsVld_Flg: invalidation-policy{data-element=tec_ChassisMgmt_BrkStsVld_Flg, handle-invalid=DONT-INVALIDATE}
      data tec_ChassisMgmt_BrkStsVld_Flg: type=boolean
    IF_ComM_IBSFLMovgDir_Enum: invalidation-policy{data-element=tec_ComM_IBSFLMovgDir_Enum, handle-invalid=DONT-INVALIDATE}
      data tec_ComM_IBSFLMovgDir_Enum: type=uint8
    IF_ComM_IBSFRMovgDir_Enum: invalidation-policy{data-element=tec_ComM_IBSFRMovgDir_Enum, handle-invalid=DONT-INVALIDATE}
      data tec_ComM_IBSFRMovgDir_Enum: type=uint8
    IF_ComM_IBSRLMovgDir_Enum: invalidation-policy{data-element=tec_ComM_IBSRLMovgDir_Enum, handle-invalid=DONT-INVALIDATE}
      data tec_ComM_IBSRLMovgDir_Enum: type=uint8
    IF_ComM_IBSRRMovgDir_Enum: invalidation-policy{data-element=tec_ComM_IBSRRMovgDir_Enum, handle-invalid=DONT-INVALIDATE}
      data tec_ComM_IBSRRMovgDir_Enum: type=uint8
    IF_ComM_IBSVehSpd_kph: invalidation-policy{data-element=tec_ComM_IBSVehSpd_kph, handle-invalid=DONT-INVALIDATE}
      data tec_ComM_IBSVehSpd_kph: type=float32
    IF_ComM_IBSVehSpdVld_Flg: invalidation-policy{data-element=tec_ComM_IBSVehSpdVld_Flg, handle-invalid=DONT-INVALIDATE}
      data tec_ComM_IBSVehSpdVld_Flg: type=boolean
    IF_ComM_MotActSpd_rpm: invalidation-policy{data-element=tec_ComM_MotActSpd_rpm, handle-invalid=DONT-INVALIDATE}
      data tec_ComM_MotActSpd_rpm: type=sint16
    IF_ComM_MotActSpdVld_Flg: invalidation-policy{data-element=tec_ComM_MotActSpdVld_Flg, handle-invalid=DONT-INVALIDATE}
      data tec_ComM_MotActSpdVld_Flg: type=boolean
    IF_ComM_MotActTq_Nm: invalidation-policy{data-element=tec_ComM_MotActTq_Nm, handle-invalid=DONT-INVALIDATE}
      data tec_ComM_MotActTq_Nm: type=float32
    IF_ComM_YRSAx_mps2q: invalidation-policy{data-element=tec_ComM_YRSAx_mps2q, handle-invalid=DONT-INVALIDATE}
      data tec_ComM_YRSAx_mps2q: type=float32
    IF_ComM_YRSAxSts_Flg: invalidation-policy{data-element=tec_ComM_YRSAxSts_Flg, handle-invalid=DONT-INVALIDATE}
      data tec_ComM_YRSAxSts_Flg: type=boolean
    IF_ErrMgmt_ComFailDTC_16bit: invalidation-policy{data-element=tec_ErrMgmt_ComFailDTC_16bit, handle-invalid=DONT-INVALIDATE}
      data tec_ErrMgmt_ComFailDTC_16bit: type=uint16
    IF_GearMgmt_ActGear_Enum: invalidation-policy{data-element=tec_GearMgmt_ActGear_Enum, handle-invalid=DONT-INVALIDATE}
      data tec_GearMgmt_ActGear_Enum: type=uint8
    IF_TorqPahMgmt_EmacQstyMaxTq_Nm: invalidation-policy{data-element=tec_TorqPahMgmt_EmacQstyMaxTq_Nm, handle-invalid=DONT-INVALIDATE}
      data tec_TorqPahMgmt_EmacQstyMaxTq_Nm: type=float32
    IF_TorqPahMgmt_EmacQstyMinTq_Nm: invalidation-policy{data-element=tec_TorqPahMgmt_EmacQstyMinTq_Nm, handle-invalid=DONT-INVALIDATE}
      data tec_TorqPahMgmt_EmacQstyMinTq_Nm: type=float32
    IF_VehMot_Acclr2Tq_Nm: invalidation-policy{data-element=tec_VehMot_Acclr2Tq_Nm, handle-invalid=DONT-INVALIDATE}
      data tec_VehMot_Acclr2Tq_Nm: type=float32
    IF_VehMot_AcclrPrpCurr_mps2q: invalidation-policy{data-element=tec_VehMot_AcclrPrpCurr_mps2q, handle-invalid=DONT-INVALIDATE}
      data tec_VehMot_AcclrPrpCurr_mps2q: type=float32
    IF_VehMot_AcclrPrpMax_mps2q: invalidation-policy{data-element=tec_VehMot_AcclrPrpMax_mps2q, handle-invalid=DONT-INVALIDATE}
      data tec_VehMot_AcclrPrpMax_mps2q: type=float32
    IF_VehMot_AcclrPrpMin_mps2q: invalidation-policy{data-element=tec_VehMot_AcclrPrpMin_mps2q, handle-invalid=DONT-INVALIDATE}
      data tec_VehMot_AcclrPrpMin_mps2q: type=float32
    IF_VehMot_SlopGrd_deg: invalidation-policy{data-element=tec_VehMot_SlopGrd_deg, handle-invalid=DONT-INVALIDATE}
      data tec_VehMot_SlopGrd_deg: type=sint8
    IF_VehMot_VehDirDif_Flg: invalidation-policy{data-element=tec_VehMot_VehDirDif_Flg, handle-invalid=DONT-INVALIDATE}
      data tec_VehMot_VehDirDif_Flg: type=boolean
    IF_VehMot_VehDragTq_Nm: invalidation-policy{data-element=tec_VehMot_VehDragTq_Nm, handle-invalid=DONT-INVALIDATE}
      data tec_VehMot_VehDragTq_Nm: type=float32
    IF_VehMot_VehSpd_kph: invalidation-policy{data-element=tec_VehMot_VehSpd_kph, handle-invalid=DONT-INVALIDATE}
      data tec_VehMot_VehSpd_kph: type=float32
    IF_VehMot_VehSpdABS_kph: invalidation-policy{data-element=tec_VehMot_VehSpdABS_kph, handle-invalid=DONT-INVALIDATE}
      data tec_VehMot_VehSpdABS_kph: type=float32
    IF_VehMot_VehSpdAcclr_mps2q: invalidation-policy{data-element=tec_VehMot_VehSpdAcclr_mps2q, handle-invalid=DONT-INVALIDATE}
      data tec_VehMot_VehSpdAcclr_mps2q: type=float32
    IF_VehMot_VehSpdVld_Flg: invalidation-policy{data-element=tec_VehMot_VehSpdVld_Flg, handle-invalid=DONT-INVALIDATE}
      data tec_VehMot_VehSpdVld_Flg: type=boolean
